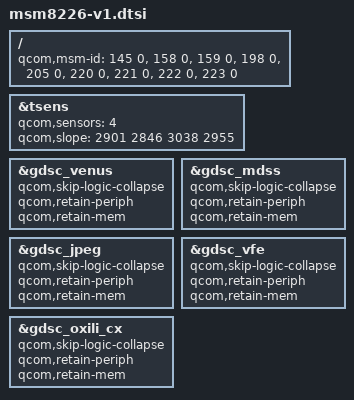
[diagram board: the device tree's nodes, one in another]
/* Copyright (c) 2013, The Linux Foundation. All rights reserved.
 *
 * This program is free software; you can redistribute it and/or modify
 * it under the terms of the GNU General Public License version 2 and
 * only version 2 as published by the Free Software Foundation.
 *
 * This program is distributed in the hope that it will be useful,
 * but WITHOUT ANY WARRANTY; without even the implied warranty of
 * MERCHANTABILITY or FITNESS FOR A PARTICULAR PURPOSE.  See the
 * GNU General Public License for more details.
 */

/*
 * As a general rule, only version-specific property overrides should be placed
 * inside this file. However, device definitions should be placed inside the
 * msm8226.dtsi file.
 */

/include/ "msm8226.dtsi"
/include/ "msm8226-v1-pm.dtsi"

/ {
	qcom,msm-id = <145 0>,
		      <158 0>,
		      <159 0>,
		      <198 0>,
		      <205 0>,
		      <220 0>,
		      <221 0>,
		      <222 0>,
		      <223 0>;
};

&tsens {
	qcom,sensors = <4>;
	qcom,slope = <2901 2846 3038 2955>;
};

&gdsc_venus {
	qcom,skip-logic-collapse;
	qcom,retain-periph;
	qcom,retain-mem;
};

&gdsc_mdss {
	qcom,skip-logic-collapse;
	qcom,retain-periph;
	qcom,retain-mem;
};

&gdsc_jpeg {
	qcom,skip-logic-collapse;
	qcom,retain-periph;
	qcom,retain-mem;
};

&gdsc_vfe {
	qcom,skip-logic-collapse;
	qcom,retain-periph;
	qcom,retain-mem;
};

&gdsc_oxili_cx {
	qcom,skip-logic-collapse;
	qcom,retain-periph;
	qcom,retain-mem;
};
